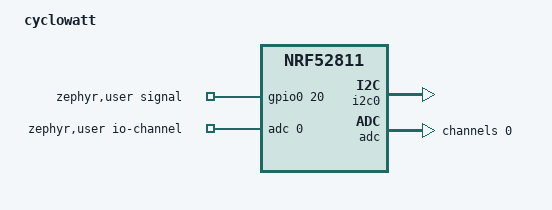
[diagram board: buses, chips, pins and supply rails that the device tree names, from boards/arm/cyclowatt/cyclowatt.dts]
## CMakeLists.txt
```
cmake_minimum_required(VERSION 3.20.0)
find_package(Zephyr REQUIRED HINTS $ENV{ZEPHYR_BASE})

project(Firmware)

target_sources(app PRIVATE src/main.c
                            src/adc_load_cell.c)
```

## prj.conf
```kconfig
# ===============================================================================================
# --- Logging Configs ---
# ===============================================================================================
CONFIG_LOG=y                    # Global switch, turns on/off the logging.
# CONFIG_LOG_MODE_MINIMAL=n       # Minimal footprint mode.
# CONFIG_PRINTK=y

CONFIG_LOG_PRINTK=y
CONFIG_USE_SEGGER_RTT=y
CONFIG_RTT_CONSOLE=y
CONFIG_LOG_BACKEND_RTT=y
CONFIG_LOG_BACKEND_UART=n

CONFIG_LOG_MODE_IMMEDIATE=y

CONFIG_SEGGER_RTT_BUFFER_SIZE_UP=4096
CONFIG_LOG_MODE_DEFERRED=y


# ===============================================================================================
# --  Peripheral Settings
# ===============================================================================================
CONFIG_GPIO=y
CONFIG_GPIO_LOG_LEVEL_DBG=y

CONFIG_I2C=y
CONFIG_I2C_LOG_LEVEL_DBG=y

CONFIG_PINCTRL=y

CONFIG_TIMING_FUNCTIONS=y
CONFIG_EVENTS=y

# Sensors
CONFIG_SENSOR=y
CONFIG_ADC=y

CONFIG_PM=y
CONFIG_PM_DEVICE=y
CONFIG_PM_DEVICE_RUNTIME=y


CONFIG_CBPRINTF_FP_SUPPORT=y  
```

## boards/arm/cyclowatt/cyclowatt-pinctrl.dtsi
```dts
&pinctrl {

  i2c1_default: i2c1_default {
    group1 {
      psels = <NRF_PSEL(TWIM_SCL, 0, 12)>, 
              <NRF_PSEL(TWIM_SDA, 0, 14)>;
    };
  };

  i2c1_sleep: i2c1_sleep {
    group1 {
      psels = <NRF_PSEL(TWIM_SCL, 0, 12)>, 
              <NRF_PSEL(TWIM_SDA, 0, 14)>;
    };
    low-power-enable;
  };

};
```

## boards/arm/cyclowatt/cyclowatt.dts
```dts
/dts-v1/;
#include <nordic/nrf52811_qfaa.dtsi>
#include "cyclowatt-pinctrl.dtsi"

/ {
	
	model = "cyclowatt";
	compatible = "eth,cyclowatt";

	chosen {
		zephyr,sram = &sram0;
		zephyr,flash = &flash0;
		zephyr,code-partition = &slot0_partition;
	};

	zephyr,user {
		signal-gpios = <&gpio0 20 GPIO_ACTIVE_HIGH>;
		io-channels = <&adc 0>;
	};
};



&i2c0 {
  status = "okay";
  pinctrl-0 = <&i2c1_sleep>;
	pinctrl-1 = <&i2c1_sleep>;
	pinctrl-names = "default", "sleep";
};

&gpio0 {
	status = "okay";
	label = "GPIO0";
};

&gpiote {
	status = "okay";
};

&flash0 {
	partitions {
		compatible = "fixed-partitions";
		#address-cells = <1>;
		#size-cells = <1>;

		boot_partition: partition@0 {
			label = "mcuboot";
			reg = <0x00000000 DT_SIZE_K(48)>;
		};

		slot0_partition: partition@c000 {
			label = "image-0";
			reg = <0x0000c000 DT_SIZE_K(56)>;
		};

		slot1_partition: partition@1a000 {
			label = "image-1";
			reg = <0x0001a000 DT_SIZE_K(56)>;
		};

		storage_partition: partition@28000 {
			label = "storage";
			reg = <0x00028000 DT_SIZE_K(32)>;
		};

	};
};

	// used for acquiring the reading of the load cell
&adc {
	status = "okay";
	#address-cells = <1>;
	#size-cells = <0>;
	thermistor0: channel@0 {
		reg = <0>;
		zephyr,gain = "ADC_GAIN_1_6";
		zephyr,reference = "ADC_REF_INTERNAL";
		zephyr,acquisition-time = <ADC_ACQ_TIME(ADC_ACQ_TIME_MICROSECONDS, 5)>;
		zephyr,input-positive = <NRF_SAADC_AIN2>;
		zephyr,resolution = <12>;
		zephyr,oversampling = <4>;
	};

};
```

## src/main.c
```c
// ===============================================================================================
// --- General Includes ---
// ===============================================================================================
#include <stdlib.h>
#include <stdint.h>
#include <stdbool.h>
#include <stdio.h>
#include <string.h>
#include <stddef.h>

// ===============================================================================================
// --- System-Specific Includes ---
// ===============================================================================================
#include <zephyr/types.h>
#include <zephyr/kernel.h>
#include <zephyr/device.h>
#include <zephyr/sys/printk.h>
#include <zephyr/sys/util.h>
#include <zephyr/logging/log.h>
#include <zephyr/drivers/gpio.h>
#include <zephyr/drivers/i2c.h>

#include "adc_load_cell.h"


// ===============================================================================================
// --- Log Module ---
// ===============================================================================================
LOG_MODULE_REGISTER(MAIN, LOG_LEVEL_DBG);


#define LSM6DS3_I2C_ADDR  0x6B
#define LSM6DS3_REG_WHOAMI 0x0F

#define ENABLE_5_V         17
#define ENABLE_SENSOR      3
uint8_t ret = 0; 

int main(void)
{
        uint8_t whoami = 0;

        const struct device* i2c1_dev = DEVICE_DT_GET(DT_NODELABEL(i2c0));
	const struct device* gpio_port = device_get_binding("GPIO0");
//*******************GPIO PIN Configuration*********************/
      //  gpio_port = DEVICE_DT_GET(GPIO_NODE);
        if (!device_is_ready(gpio_port)) {
                printk("Error: GPIO device not ready\n");
        }
        gpio_pin_configure(gpio_port, ENABLE_5_V, GPIO_OUTPUT_HIGH);
        gpio_pin_configure(gpio_port, ENABLE_SENSOR, GPIO_OUTPUT_HIGH);


//*******************GPIO PIN Configuration*********************/
        ret = device_is_ready(i2c1_dev);
	if(ret != true){
	        LOG_INF("I2C device is not ready, with error code:  %d\n", ret);
	}	

/***************************Init********************************/
        adc_init();

        double load_cell_readout = 0; 

        while(true){
            
                LOG_INF("Running...");
                load_cell_readout = get_thermistor_data();
                LOG_INF("Load cell %f", load_cell_readout);
                k_sleep(K_MSEC(1000));
        }
}

/*
        ret = i2c_reg_read_byte(i2c1_dev, LSM6DS3_I2C_ADDR, LSM6DS3_REG_WHOAMI, &whoami);
        if (ret < 0) {
                LOG_ERR("Failed to read WHO_AM_I: %d", ret);
        }

        LOG_INF("LSM6DS3 WHO_AM_I = 0x%02x", whoami);
        if (whoami == 0x69) {
                LOG_INF("Device detected correctly!");
        } else {
                LOG_WRN("Unexpected WHO_AM_I response: %d ", whoami);
        }

        }

*/
```

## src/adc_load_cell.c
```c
#include "adc_load_cell.h"

LOG_MODULE_REGISTER(ADC_LOAD_CELL, LOG_LEVEL_DBG);


#define NRFX_SAADC_ENABLED 1
#define SAADC_ENABLED 1

// begin ADC checks
#if !DT_NODE_EXISTS(DT_PATH(zephyr_user)) || \
	!DT_NODE_HAS_PROP(DT_PATH(zephyr_user), io_channels)
#endif

#define DT_SPEC_AND_COMMA(node_id, prop, idx) \
ADC_DT_SPEC_GET_BY_IDX(node_id, idx),
/*ADC Voltage reading*/
/* Data of ADC io-channels specified in devicetree. */
static const struct adc_dt_spec adc_channels[] = {
	DT_FOREACH_PROP_ELEM(DT_PATH(zephyr_user), io_channels,
			     DT_SPEC_AND_COMMA)
};

void adc_init(void){
	int err;

	/* Configure channels individually prior to sampling. */
	for (size_t i = 0U; i < ARRAY_SIZE(adc_channels); i++) {
		if (!device_is_ready(adc_channels[i].dev)) {
			printk("ADC controller device %s not ready\n", adc_channels[i].dev->name);
			return;
		}

		err = adc_channel_setup_dt(&adc_channels[i]);
		if (err < 0) {
			printk("Could not setup adc channel #%d (%d)\n", i, err);
			return;
		}
	}
	return;
}

// gets thermistor temperature and writes it into the sensor_data struct by using adc and LUT
// If the temperature is out of the range covered in the LUT, a very large value gets returned to make clear that it's an unrealistic value - this is the case e.g. if the thermistor is not connected
double get_thermistor_data(void){
	int err;
	uint16_t buf;
	struct adc_sequence sequence = {
		.buffer = &buf,
		/* buffer size in bytes, not number of samples */
		.buffer_size = sizeof(buf),
	};

	(void)adc_sequence_init_dt(&adc_channels[0], &sequence);

	err = adc_read(adc_channels[0].dev, &sequence);
	if (err < 0) {
		printk("Could not read using adc_read() (%d)\n", err);
	}

	/*
	* If using differential mode, the 16 bit value
	* in the ADC sample buffer should be a signed 2's
	* complement value.
	*/
	int32_t val_raw;
	if (adc_channels[0].channel_cfg.differential) {
		val_raw = (int32_t)((int16_t)buf);
	} else {
		val_raw = (int32_t)buf;
	}

	int32_t val_mv = val_raw;
	err = adc_raw_to_millivolts_dt(&adc_channels[0], &val_mv);
	if (err < 0) {
		printk(" (value in mV not available)\n");
	}
	val_raw = (int32_t)(((val_mv*4096)/(3300)));

	return val_raw; 
}
```

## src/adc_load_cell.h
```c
#include <zephyr/kernel.h>
#include <zephyr/device.h>
#include <zephyr/drivers/sensor.h>
#include <zephyr/logging/log.h>
#include <zephyr/drivers/i2c.h>

// ADC includes
#include <nrfx_saadc.h>
#include <zephyr/drivers/adc.h>

#include <zephyr/devicetree.h>
#include <zephyr/sys/util.h>
#include <math.h>

void adc_init(void);
double get_thermistor_data(void);
```
